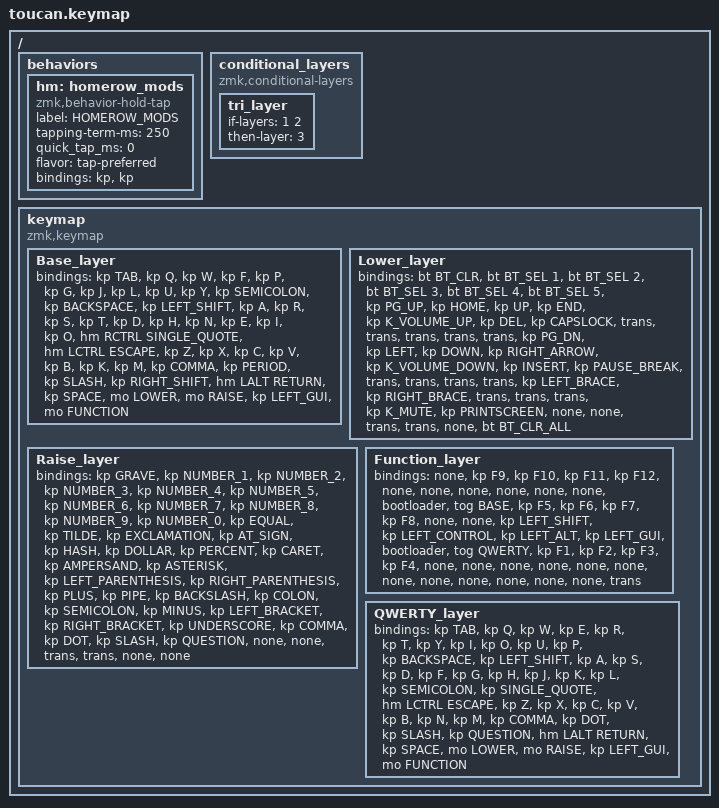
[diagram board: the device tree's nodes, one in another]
#include <behaviors.dtsi>
#include <dt-bindings/zmk/keys.h>
#include <dt-bindings/zmk/bt.h>
#include <dt-bindings/zmk/reset.h>
#include <dt-bindings/zmk/outputs.h>

#define BASE 0
#define LOWER 1
#define RAISE 2
#define FUNCTION 3
#define QWERTY 4

/ {
  behaviors {
    hm: homerow_mods {
      compatible = "zmk,behavior-hold-tap";
      label = "HOMEROW_MODS";
      #binding-cells = <2>;
      tapping-term-ms = <250>;
      quick_tap_ms = <0>;
      flavor = "tap-preferred";
      bindings = <&kp>, <&kp>;
    };
  };

    conditional_layers {
        compatible = "zmk,conditional-layers";
        tri_layer {
            if-layers = <1 2>;
            then-layer = <3>;
        };
    };

    keymap {
        compatible = "zmk,keymap";

    Base_layer {
      bindings = <
        &kp TAB &kp Q &kp W &kp F &kp P &kp G &kp J &kp L &kp U &kp Y &kp SEMICOLON &kp BACKSPACE &kp LEFT_SHIFT &kp A &kp R &kp S &kp T &kp D &kp H &kp N &kp E &kp I &kp O &hm RCTRL SINGLE_QUOTE &hm LCTRL ESCAPE &kp Z &kp X &kp C &kp V &kp B &kp K &kp M &kp COMMA &kp PERIOD &kp SLASH &kp RIGHT_SHIFT &hm LALT RETURN &kp SPACE &mo LOWER &mo RAISE &kp LEFT_GUI &mo FUNCTION 
      >;
    };

    Lower_layer {
      bindings = <
        &bt BT_CLR &bt BT_SEL 1 &bt BT_SEL 2 &bt BT_SEL 3 &bt BT_SEL 4 &bt BT_SEL 5 &kp PG_UP &kp HOME &kp UP &kp END &kp K_VOLUME_UP &kp DEL &kp CAPSLOCK &trans &trans &trans &trans &trans &kp PG_DN &kp LEFT &kp DOWN &kp RIGHT_ARROW &kp K_VOLUME_DOWN &kp INSERT &kp PAUSE_BREAK &trans &trans &trans &trans &kp LEFT_BRACE &kp RIGHT_BRACE &trans &trans &trans &kp K_MUTE &kp PRINTSCREEN &none &none &trans &trans &none &bt BT_CLR_ALL 
      >;
    };

    Raise_layer {
      bindings = <
        &kp GRAVE &kp NUMBER_1 &kp NUMBER_2 &kp NUMBER_3 &kp NUMBER_4 &kp NUMBER_5 &kp NUMBER_6 &kp NUMBER_7 &kp NUMBER_8 &kp NUMBER_9 &kp NUMBER_0 &kp EQUAL &kp TILDE &kp EXCLAMATION &kp AT_SIGN &kp HASH &kp DOLLAR &kp PERCENT &kp CARET &kp AMPERSAND &kp ASTERISK &kp LEFT_PARENTHESIS &kp RIGHT_PARENTHESIS &kp PLUS &kp PIPE &kp BACKSLASH &kp COLON &kp SEMICOLON &kp MINUS &kp LEFT_BRACKET &kp RIGHT_BRACKET &kp UNDERSCORE &kp COMMA &kp DOT &kp SLASH &kp QUESTION &none &none &trans &trans &none &none 
      >;
    };

    Function_layer {
      bindings = <
        &none &kp F9 &kp F10 &kp F11 &kp F12 &none &none &none &none &none &none &bootloader &tog BASE &kp F5 &kp F6 &kp F7 &kp F8 &none &none &kp LEFT_SHIFT &kp LEFT_CONTROL &kp LEFT_ALT &kp LEFT_GUI &bootloader &tog QWERTY &kp F1 &kp F2 &kp F3 &kp F4 &none &none &none &none &none &none &none &none &none &none &none &none &trans 
      >;
    };

    QWERTY_layer {
      bindings = <
        &kp TAB &kp Q &kp W &kp E &kp R &kp T &kp Y &kp I &kp O &kp U &kp P &kp BACKSPACE &kp LEFT_SHIFT &kp A &kp S &kp D &kp F &kp G &kp H &kp J &kp K &kp L &kp SEMICOLON &kp SINGLE_QUOTE &hm LCTRL ESCAPE &kp Z &kp X &kp C &kp V &kp B &kp N &kp M &kp COMMA &kp DOT &kp SLASH &kp QUESTION &hm LALT RETURN &kp SPACE &mo LOWER &mo RAISE &kp LEFT_GUI &mo FUNCTION 
      >;
    };

    };
};
